VERSION ""

NS_ :

BS_:

BU_:

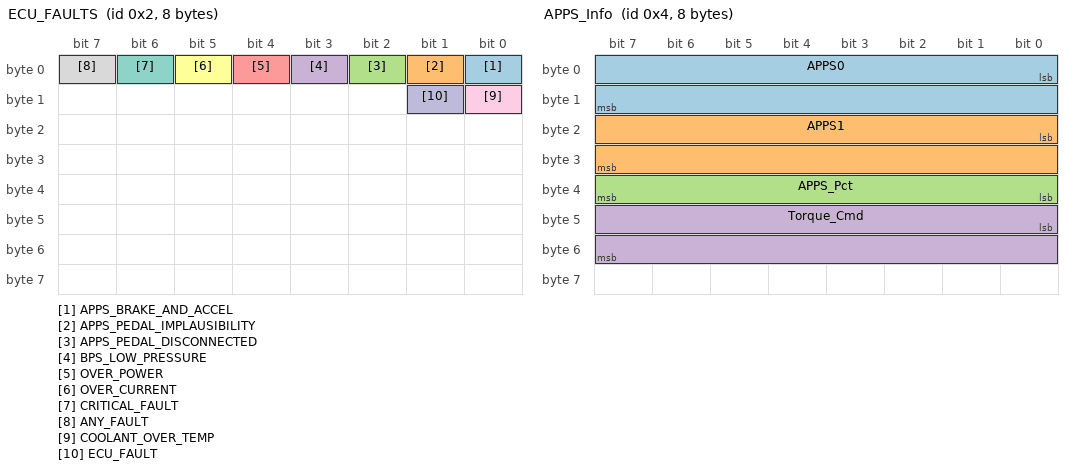
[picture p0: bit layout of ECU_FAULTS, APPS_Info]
BO_ 2 ECU_FAULTS: 8 Vector__XXX
 SG_ APPS_BRAKE_AND_ACCEL : 0|1@1+ (1,0) [0|0] "" Vector__XXX
 SG_ APPS_PEDAL_IMPLAUSIBILITY : 1|1@1+ (1,0) [0|0] "" Vector__XXX
 SG_ APPS_PEDAL_DISCONNECTED : 2|1@1+ (1,0) [0|0] "" Vector__XXX
 SG_ BPS_LOW_PRESSURE : 3|1@1+ (1,0) [0|0] "" Vector__XXX
 SG_ OVER_POWER : 4|1@1+ (1,0) [0|0] "" Vector__XXX
 SG_ OVER_CURRENT : 5|1@1+ (1,0) [0|0] "" Vector__XXX
 SG_ CRITICAL_FAULT : 6|1@1+ (1,0) [0|0] "" Vector__XXX
 SG_ ANY_FAULT : 7|1@1+ (1,0) [0|0] "" Vector__XXX
 SG_ COOLANT_OVER_TEMP : 8|1@1+ (1,0) [0|0] "" Vector__XXX
 SG_ ECU_FAULT : 9|1@1+ (1,0) [0|0] "" Vector__XXX

BO_ 3 MC_FAULTS: 8 Vector__XXX
 SG_ Fault32_MotorOvrSpd : 0|1@1+ (1,0) [0|0] "" Vector__XXX
 SG_ Fault33_OvrCurr : 1|1@1+ (1,0) [0|0] "" Vector__XXX
 SG_ Fault34_OvrVolt : 2|1@1+ (1,0) [0|0] "" Vector__XXX
 SG_ Fault35_InvOvrTemp : 3|1@1+ (1,0) [0|0] "" Vector__XXX
 SG_ Fault36_AccInputShorted : 4|1@1+ (1,0) [0|0] "" Vector__XXX
 SG_ Fault37_AccInputOpn : 5|1@1+ (1,0) [0|0] "" Vector__XXX
 SG_ Fault38_DirectionCommand : 6|1@1+ (1,0) [0|0] "" Vector__XXX
 SG_ Fault39_InvResponseTimeOut : 7|1@1+ (1,0) [0|0] "" Vector__XXX
 SG_ Fault40_HW_Gate_DeSat : 8|1@1+ (1,0) [0|0] "" Vector__XXX
 SG_ Fault41_HardwareOvrCurrent : 9|1@1+ (1,0) [0|0] "" Vector__XXX
 SG_ Fault42_UnderVolt : 10|1@1+ (1,0) [0|0] "" Vector__XXX
 SG_ Fault43_CANCmdMsgLost : 11|1@1+ (1,0) [0|0] "" Vector__XXX
 SG_ Fault44_MotorOvrTemp : 12|1@1+ (1,0) [0|0] "" Vector__XXX
 SG_ Fault48_BrakeInputShorted : 13|1@1+ (1,0) [0|0] "" Vector__XXX
 SG_ Fault49_BrakeInputOpn : 14|1@1+ (1,0) [0|0] "" Vector__XXX
 SG_ Fault50_ModuleA_OvrTemp : 15|1@1+ (1,0) [0|0] "" Vector__XXX
 SG_ Fault51_ModuleB_OvrTemp : 16|1@1+ (1,0) [0|0] "" Vector__XXX
 SG_ Fault52_ModuleC_OvrTemp : 17|1@1+ (1,0) [0|0] "" Vector__XXX
 SG_ Fault53_PCB_OvrTemp : 18|1@1+ (1,0) [0|0] "" Vector__XXX
 SG_ Fault54_GateDriveBoard1_OvrTemp : 19|1@1+ (1,0) [0|0] "" Vector__XXX
 SG_ Fault55_GateDriveBoard2_OvrTemp : 20|1@1+ (1,0) [0|0] "" Vector__XXX
 SG_ Fault56_GateDriveBoard3_OvrTemp : 21|1@1+ (1,0) [0|0] "" Vector__XXX
 SG_ Fault57_CurrentSensor : 22|1@1+ (1,0) [0|0] "" Vector__XXX
 SG_ Fault59_HardwareDCBus_OvrVolt : 23|1@1+ (1,0) [0|0] "" Vector__XXX
 SG_ Fault62_Resolver_NotConn : 24|1@1+ (1,0) [0|0] "" Vector__XXX
 SG_ ANY_MC_FAULT : 25|1@1+ (1,0) [0|0] "" Vector__XXX

BO_ 4 APPS_Info: 8 Vector__XXX
 SG_ APPS0 : 0|16@1+ (1,0) [0|0] "" Vector__XXX
 SG_ APPS1 : 16|16@1+ (1,0) [0|0] "" Vector__XXX
 SG_ APPS_Pct : 32|8@1+ (1,0) [0|0] "" Vector__XXX
 SG_ Torque_Cmd : 40|16@1- (1,0) [0|0] "" Vector__XXX

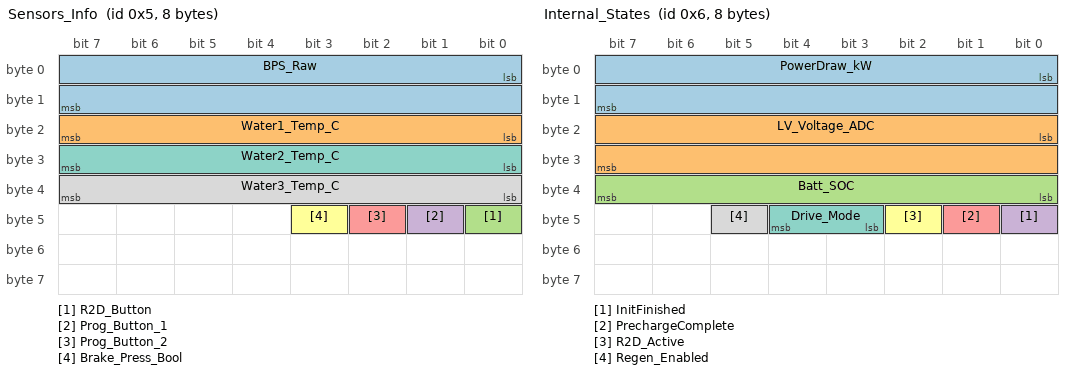
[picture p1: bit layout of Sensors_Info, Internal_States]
BO_ 5 Sensors_Info: 8 Vector__XXX
 SG_ BPS_Raw : 0|16@1+ (1,0) [0|0] "" Vector__XXX
 SG_ Water1_Temp_C : 16|8@1+ (1,0) [0|0] "" Vector__XXX
 SG_ R2D_Button : 40|1@1+ (1,0) [0|0] "" Vector__XXX
 SG_ Prog_Button_1 : 41|1@1+ (1,0) [0|0] "" Vector__XXX
 SG_ Prog_Button_2 : 42|1@1+ (1,0) [0|0] "" Vector__XXX
 SG_ Brake_Press_Bool : 43|1@1+ (1,0) [0|0] "" Vector__XXX
 SG_ Water2_Temp_C : 24|8@1+ (1,0) [0|0] "" Vector__XXX
 SG_ Water3_Temp_C : 32|8@1+ (1,0) [0|0] "" Vector__XXX

BO_ 6 Internal_States: 8 Vector__XXX
 SG_ PowerDraw_kW : 0|16@1+ (1,0) [0|0] "" Vector__XXX
 SG_ LV_Voltage_ADC : 16|16@1+ (1,0) [0|0] "" Vector__XXX
 SG_ Batt_SOC : 32|8@1+ (1,0) [0|0] "" Vector__XXX
 SG_ InitFinished : 40|1@1+ (1,0) [0|0] "" Vector__XXX
 SG_ PrechargeComplete : 41|1@1+ (1,0) [0|0] "" Vector__XXX
 SG_ R2D_Active : 42|1@1+ (1,0) [0|0] "" Vector__XXX
 SG_ Drive_Mode : 43|2@1+ (1,0) [0|0] "" Vector__XXX
 SG_ Regen_Enabled : 45|1@1+ (1,0) [0|0] "" Vector__XXX

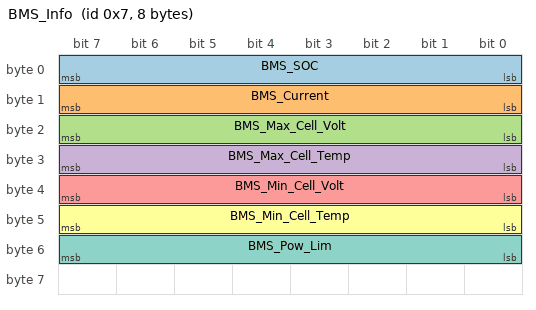
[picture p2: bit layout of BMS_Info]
BO_ 7 BMS_Info: 8 Vector__XXX
 SG_ BMS_SOC : 0|8@1+ (0.392156863,0) [0|100] "%" Vector__XXX
 SG_ BMS_Current : 8|8@1+ (0.78125,0) [0|200] "A" Vector__XXX
 SG_ BMS_Max_Cell_Volt : 16|8@1+ (0.019607843,0) [0|5] "V" Vector__XXX
 SG_ BMS_Max_Cell_Temp : 24|8@1+ (0.588235294,0) [0|150] "C" Vector__XXX
 SG_ BMS_Min_Cell_Volt : 32|8@1+ (0.019607843,0) [0|5] "V" Vector__XXX
 SG_ BMS_Min_Cell_Temp : 40|8@1+ (0.588235294,0) [0|150] "C" Vector__XXX
 SG_ BMS_Pow_Lim : 48|8@1+ (1,0) [0|80] "kW" Vector__XXX
